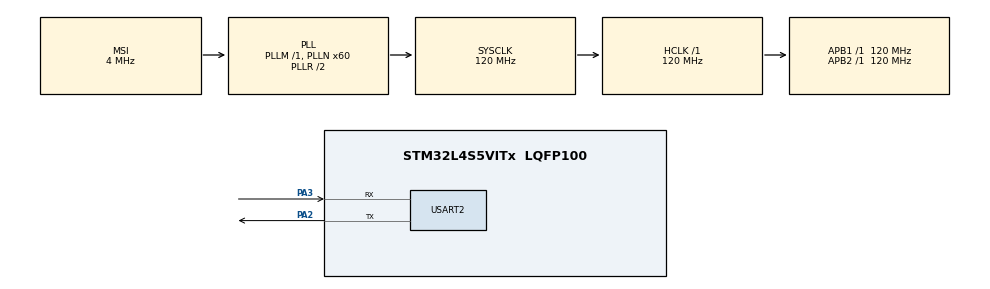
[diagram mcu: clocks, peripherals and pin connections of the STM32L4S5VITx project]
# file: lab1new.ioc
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Mcu.Family=STM32L4
Mcu.Name=STM32L4S5VITx
Mcu.Package=LQFP100
NVIC.PriorityGroup=NVIC_PRIORITYGROUP_4
PA13\ (JTMS/SWDIO).Signal=SYS_JTMS-SWDIO
PA2.Mode=Asynchronous
PA2.Signal=USART2_TX
PA3.Mode=Asynchronous
PA3.Signal=USART2_RX
PB3\ (JTDO/TRACESWO).Signal=SYS_JTDO-SWO
ProjectManager.HeapSize=0x200
ProjectManager.StackSize=0x400
ProjectManager.TargetToolchain=STM32CubeIDE
RCC.ADCFreq_Value=48000000
RCC.AHBFreq_Value=120000000
RCC.APB1Freq_Value=120000000
RCC.APB1TimFreq_Value=120000000
RCC.APB2Freq_Value=120000000
RCC.APB2TimFreq_Value=120000000
RCC.CortexFreq_Value=120000000
RCC.HCLKFreq_Value=120000000
RCC.HSE_VALUE=8000000
RCC.HSI48_VALUE=48000000
RCC.HSI_VALUE=16000000
RCC.LSE_VALUE=32768
RCC.MSI_VALUE=4000000
RCC.PLLN=60
RCC.PLLSAI1N=24
RCC.SYSCLKFreq_VALUE=120000000
RCC.SYSCLKSource=RCC_SYSCLKSOURCE_PLLCLK
RCC.USBFreq_Value=48000000
RCC.VCOOutputFreq_Value=240000000
USART2.VirtualMode-Asynchronous=VM_ASYNC
board=B-L4S5I-IOT01A

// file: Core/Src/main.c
/* USER CODE BEGIN Header */
/**
  ******************************************************************************
  * @file           : main.c
  * @brief          : Main program body
  ******************************************************************************
  * @attention
  *
  * Copyright (c) 2023 STMicroelectronics.
  * All rights reserved.
  *
  * This software is licensed under terms that can be found in the LICENSE file
  * in the root directory of this software component.
  * If no LICENSE file comes with this software, it is provided AS-IS.
  *
  ******************************************************************************
  */
/* USER CODE END Header */
#include "main.h"

/* USER CODE BEGIN Includes */
#include "arm_math.h"
#include "utility.h"
#define ARM_MATH_CM4
#include <stdio.h>
/* USER CODE END Includes */

/* USER CODE BEGIN PD */
#define ITM_Port32(n) (*((volatile unsigned long *) (0xE0000000+4*n)))
/* USER CODE END PD */

UART_HandleTypeDef huart2;

void SystemClock_Config(void);
static void MX_GPIO_Init(void);
static void MX_USART2_UART_Init(void);
/* USER CODE BEGIN PFP */
#ifdef __GNUC__
#define PUTCHAR_PROTOTYPE int __io_putchar(int ch)
#else
#define PUTCHAR_PROTOTYPE int fputc(int ch, FILE *f)
#endif

PUTCHAR_PROTOTYPE
{
  HAL_UART_Transmit(&huart2, (uint8_t *)&ch, 1, HAL_MAX_DELAY);
  return ch;
}
/* USER CODE END PFP */

/* USER CODE BEGIN 0 */
int kalmanfilter(float* InputArray, float* OutputArray, kstate* ks, uint32_t length);
extern int kalmanfilter_asm2(kstate* ks, float meas);
extern int kalmanfilter_asm(float* InputArray, float* OutputArray, kstate* ks, uint32_t Length);
int kalmanfilter_DSP(float* InputArray, float* OutputArray, kstate* ks, uint32_t Length);
float stddev(float* vec, float* output, int N);
//float std(float* input, uint32_t length);
int statistics(float* InputArray, float* OutputArray, uint32_t length, float* corr, float* conv);
/* USER CODE END 0 */

int main(void)
{
  /* USER CODE BEGIN 1 */
  printf("hello");
  /* USER CODE END 1 */

  /* MCU Configuration--------------------------------------------------------*/

  /* Reset of all peripherals, Initializes the Flash interface and the Systick. */
  HAL_Init();

  /* Configure the system clock */
  SystemClock_Config();

  /* Initialize all configured peripherals */
  MX_GPIO_Init();
  MX_USART2_UART_Init();
  /* USER CODE BEGIN 2 */
  kstate kalman_state = { .k =0.0, .p=0.1, .q=0.1, .r=0.1, .x =5.0};
  float InputArray1[5] = {0,1,2,3,4};
  float meas = 3.57;
  float InputArray[] = {10.4915760032, 10.1349974709, 9.53992591829, 9.60311878706,
  					10.4858891793, 10.1104642352, 9.51066931906, 9.75755656493,
  					9.82154078273, 10.2906541933, 10.4861328671, 9.57321181356,
  					9.70882714139, 10.4359069357, 9.70644021369, 10.2709894039,
  					10.0823149505, 10.2954563443, 9.57130449017, 9.66832136479,
  					10.4521677502, 10.4287240667, 10.1833650752, 10.0066049721,
  					10.3279461634, 10.4767210803, 10.3790964606, 10.1937408814,
  					10.0318963522, 10.4939180917, 10.2381858895, 9.59703103024,
  					9.62757986516, 10.1816981174, 9.65703773168, 10.3905666599,
  					10.0941977598, 9.93515274393, 9.71017053437, 10.0303874259,
  					10.0173504397, 9.69022731474, 9.73902896102, 9.52524419732,
  					10.3270730526, 9.54695650657, 10.3573960542, 9.88773266876,
  					10.1685038683, 10.1683694089, 9.88406620159, 10.3290065898,
  					10.2547227265, 10.4733422906, 10.0133952458, 10.4205693583,
  					9.71335255372, 9.89061396699, 10.1652744131, 10.2580948608,
  					10.3465431058, 9.98446410493, 9.79376005657, 10.202518901,
  					9.83867150985, 9.89532986869, 10.2885062658, 9.97748768804,
  					10.0403923759, 10.1538911808, 9.78303667556, 9.72420149909,
  					9.59117495073, 10.1716116012, 10.2015818969, 9.90650056596,
  					10.3251329834, 10.4550120431, 10.4925749165, 10.1548177178,
  					9.60547133785, 10.4644672766, 10.2326496615, 10.2279703226,
  					10.3535284606, 10.2437410625, 10.3851531317, 9.90784804928,
  					9.98208344925, 9.52778805729, 9.69323876912, 9.92987312087,
  					9.73938925207, 9.60543743477, 9.79600805462, 10.4950988486,
  					10.2814361401, 9.7985283333, 9.6287888922, 10.4491538991,
  					9.5799256668};
  uint32_t length = (uint32_t) (sizeof(InputArray)/sizeof(InputArray[0]));
  float OutputArray[((int)(sizeof(InputArray)/sizeof(InputArray[0])))];
  float dev;
  float32_t dev1;
  float convolutionDSP[(int)(2*length-1)];
  float correlationDSP[(int)(2*length-1)];
  float conv[(int)(2*length-1)];
  float corr[(int)(2*length-1)];
  /* USER CODE END 2 */

  /* Infinite loop */
  while (1)
  {

    /* USER CODE BEGIN 3 */
	  printf("hello");

	  //assembly
//	  kalmanfilter_asm2(&kalman_state, meas);
	  kalmanfilter_asm(&InputArray, &OutputArray, &kalman_state, length);
//	  kalmanfilter(&InputArray, &OutputArray, &kalman_state, length);
//	  kalmanfilter_DSP(&InputArray, &OutputArray, &kalman_state, length);

	  ITM_Port32(31) =1;
//	  arm_conv_f32(&InputArray, length, &OutputArray, length, convolutionDSP);
//	  arm_correlate_f32(&InputArray, length, &OutputArray, length, correlationDSP);
	  dev = stddev(&InputArray, &OutputArray, length);
	  ITM_Port32(31) =2;
//	  statistics(&InputArray, &OutputArray, length, corr, conv);
	  arm_std_f32(&InputArray, length, &dev1);
	  ITM_Port32(31) = 3;
	  int aaa = 3;

  }
  /* USER CODE END 3 */
}

void SystemClock_Config(void)
{
  RCC_OscInitTypeDef RCC_OscInitStruct = {0};
  RCC_ClkInitTypeDef RCC_ClkInitStruct = {0};

  /** Configure the main internal regulator output voltage
  */
  if (HAL_PWREx_ControlVoltageScaling(PWR_REGULATOR_VOLTAGE_SCALE1_BOOST) != HAL_OK)
  {
    Error_Handler();
  }

  /** Initializes the RCC Oscillators according to the specified parameters
  * in the RCC_OscInitTypeDef structure.
  */
  RCC_OscInitStruct.OscillatorType = RCC_OSCILLATORTYPE_MSI;
  RCC_OscInitStruct.MSIState = RCC_MSI_ON;
  RCC_OscInitStruct.MSICalibrationValue = 0;
  RCC_OscInitStruct.MSIClockRange = RCC_MSIRANGE_6;
  RCC_OscInitStruct.PLL.PLLState = RCC_PLL_ON;
  RCC_OscInitStruct.PLL.PLLSource = RCC_PLLSOURCE_MSI;
  RCC_OscInitStruct.PLL.PLLM = 1;
  RCC_OscInitStruct.PLL.PLLN = 60;
  RCC_OscInitStruct.PLL.PLLP = RCC_PLLP_DIV2;
  RCC_OscInitStruct.PLL.PLLQ = RCC_PLLQ_DIV2;
  RCC_OscInitStruct.PLL.PLLR = RCC_PLLR_DIV2;
  if (HAL_RCC_OscConfig(&RCC_OscInitStruct) != HAL_OK)
  {
    Error_Handler();
  }

  /** Initializes the CPU, AHB and APB buses clocks
  */
  RCC_ClkInitStruct.ClockType = RCC_CLOCKTYPE_HCLK|RCC_CLOCKTYPE_SYSCLK
                              |RCC_CLOCKTYPE_PCLK1|RCC_CLOCKTYPE_PCLK2;
  RCC_ClkInitStruct.SYSCLKSource = RCC_SYSCLKSOURCE_PLLCLK;
  RCC_ClkInitStruct.AHBCLKDivider = RCC_SYSCLK_DIV1;
  RCC_ClkInitStruct.APB1CLKDivider = RCC_HCLK_DIV1;
  RCC_ClkInitStruct.APB2CLKDivider = RCC_HCLK_DIV1;

  if (HAL_RCC_ClockConfig(&RCC_ClkInitStruct, FLASH_LATENCY_5) != HAL_OK)
  {
    Error_Handler();
  }
}

static void MX_USART2_UART_Init(void)
{

  huart2.Instance = USART2;
  huart2.Init.BaudRate = 115200;
  huart2.Init.WordLength = UART_WORDLENGTH_8B;
  huart2.Init.StopBits = UART_STOPBITS_1;
  huart2.Init.Parity = UART_PARITY_NONE;
  huart2.Init.Mode = UART_MODE_TX_RX;
  huart2.Init.HwFlowCtl = UART_HWCONTROL_NONE;
  huart2.Init.OverSampling = UART_OVERSAMPLING_16;
  huart2.Init.OneBitSampling = UART_ONE_BIT_SAMPLE_DISABLE;
  huart2.Init.ClockPrescaler = UART_PRESCALER_DIV1;
  huart2.AdvancedInit.AdvFeatureInit = UART_ADVFEATURE_NO_INIT;
  if (HAL_UART_Init(&huart2) != HAL_OK)
  {
    Error_Handler();
  }
  if (HAL_UARTEx_SetTxFifoThreshold(&huart2, UART_TXFIFO_THRESHOLD_1_8) != HAL_OK)
  {
    Error_Handler();
  }
  if (HAL_UARTEx_SetRxFifoThreshold(&huart2, UART_RXFIFO_THRESHOLD_1_8) != HAL_OK)
  {
    Error_Handler();
  }
  if (HAL_UARTEx_DisableFifoMode(&huart2) != HAL_OK)
  {
    Error_Handler();
  }

}

static void MX_GPIO_Init(void)
{

  /* GPIO Ports Clock Enable */
  __HAL_RCC_GPIOA_CLK_ENABLE();
  __HAL_RCC_GPIOB_CLK_ENABLE();

}

void Error_Handler(void)
{
  __disable_irq();
  while (1)
  {
  }
}
